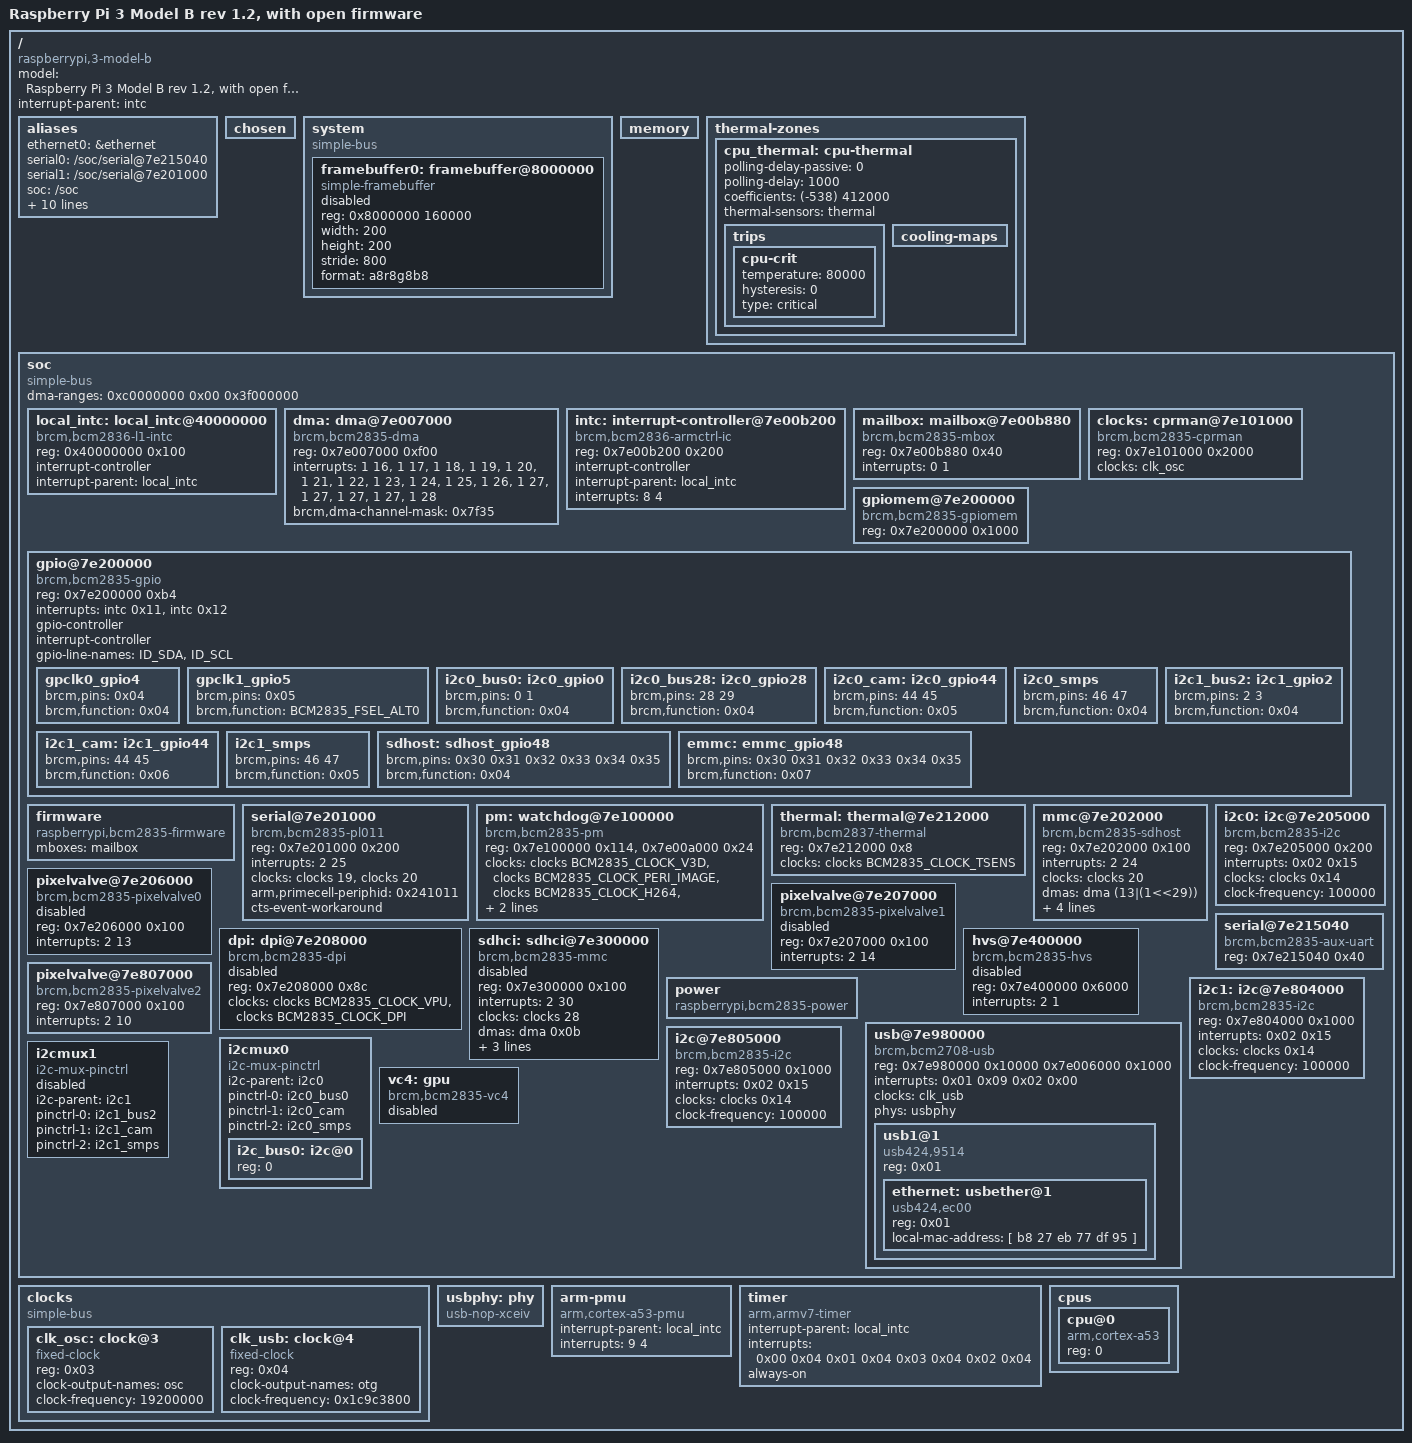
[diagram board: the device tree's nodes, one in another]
/dts-v1/;

// #define IRQ_TYPE_LEVEL_HIGH      4

#define BCM2835_FSEL_ALT0 4

#define BCM2835_CLOCK_VPU           20
#define BCM2835_CLOCK_V3D           21
#define BCM2835_CLOCK_ISP           22
#define BCM2835_CLOCK_H264          23
#define BCM2835_CLOCK_TSENS         27
#define BCM2835_CLOCK_PERI_IMAGE    29
#define BCM2835_CLOCK_DPI           44


/memreserve/ 0x00000000 0x00001000;
// /memreserve/ 0x20000000 0x1000000; // 16mb of MMIO

/ {
  compatible = "raspberrypi,3-model-b", "brcm,bcm2837";
  model = "Raspberry Pi 3 Model B rev 1.2, with open firmware";
  #address-cells = <0x01>;
  #size-cells = <0x01>;
  interrupt-parent = <&intc>;

  aliases {
    ethernet0 = &ethernet;
    serial0 = "/soc/serial@7e215040";
    serial1 = "/soc/serial@7e201000";
    soc = "/soc";
    dma = "/soc/dma@7e007000";
    intc = "/soc/interrupt-controller@7e00b200";
    uart0 = "/soc/serial@7e201000";
    sdhost = "/soc/mmc@7e202000";
    mmc0 = "/soc/mmc@7e202000";
    i2c0 = "/soc/i2c@7e205000";
    uart1 = "/soc/serial@7e215040";
    i2c1 = "/soc/i2c@7e804000";
    i2c2 = "/soc/i2c@7e805000";
    usb = "/soc/usb@7e980000";
  };
  chosen {
  };
  system {
    compatible = "simple-bus";
    #address-cells = <1>;
    #size-cells = <1>;
    ranges = <>;
    framebuffer0: framebuffer@8000000 {
      compatible = "simple-framebuffer";
      reg = <0x8000000 160000>;
      width = <200>;
      height = <200>;
      stride = <800>;
      format = "a8r8g8b8";
      status = "disabled"; // disabled by default, the bootloader will fill in the right numbers, and enable
    };
  };
  memory {
    device_type = "memory";
  };
  /*
  leds: leds {
    compatible = "gpio-leds";
    act {
      label = "ACT";
      default-state = "keep";
      linux,default-trigger = "heartbeat";
      gpios = <&gpio XX GPIO_ACTIVE_HIGH>;
    };
  };
  */
  thermal-zones {
    cpu_thermal: cpu-thermal {
      polling-delay-passive = <0>;
      polling-delay = <1000>;
      //              slope  offset
      coefficients = <(-538) 412000>;

      thermal-sensors = <&thermal>;

      trips {
        cpu-crit {
          temperature = <80000>;
          hysteresis  = <0>;
          type        = "critical";
        };
      };

      cooling-maps {
      };
    };
  };
  soc {
    compatible = "simple-bus";
    #address-cells = <1>;
    #size-cells = <1>;
    //        child       parent       length
    ranges = <0x7e000000 0x20000000 0x1000000 /* map the MMIO space to 0x3f000000 in arm, 16mb long */
              0x40000000 0x40000000 0x1000>; /* identity map the local_intc, 0x1000 bytes long */
    dma-ranges = <0xc0000000 0x00 0x3f000000>; /* map arm physical 0 to the uncached alias, 1008mb long */


    local_intc: local_intc@40000000 {
      compatible = "brcm,bcm2836-l1-intc";
      reg = <0x40000000 0x100>;
      interrupt-controller;
      #interrupt-cells = <2>;
      interrupt-parent = <&local_intc>;
    };
    dma: dma@7e007000 {
      compatible = "brcm,bcm2835-dma";
      reg = <0x7e007000 0xf00>;
      interrupts = <1 16>,
                   <1 17>,
                   <1 18>,
                   <1 19>,
                   <1 20>,
                   <1 21>,
                   <1 22>,
                   <1 23>,
                   <1 24>,
                   <1 25>,
                   <1 26>,
                   /* dma channel 11-14 share one irq */
                   <1 27>,
                   <1 27>,
                   <1 27>,
                   <1 27>,
                   /* unused shared irq for all channels */
                   <1 28>;
      interrupt-names = "dma0",
                        "dma1",
                        "dma2",
                        "dma3",
                        "dma4",
                        "dma5",
                        "dma6",
                        "dma7",
                        "dma8",
                        "dma9",
                        "dma10",
                        "dma11",
                        "dma12",
                        "dma13",
                        "dma14",
                        "dma-shared-all";
      #dma-cells = <1>;
      brcm,dma-channel-mask = <0x7f35>;
    };
    /*axiperf: axiperf {
      compatible = "brcm,bcm2835-axiperf";
      reg = <0x7e009800 0x100>,
            <0x7ee08000 0x100>;
      firmware = <&firmware>;
      //status = "disabled";
    };*/
    intc: interrupt-controller@7e00b200 {
      compatible = "brcm,bcm2836-armctrl-ic";
      reg = <0x7e00b200 0x200>;
      interrupt-controller;
      #interrupt-cells = <0x02>;
      interrupt-parent = <&local_intc>;
      interrupts = <8 4>;
    };
    mailbox: mailbox@7e00b880 {
      compatible = "brcm,bcm2835-mbox";
      reg = <0x7e00b880 0x40>;
      interrupts = <0 1>;
      #mbox-cells = <0>;
    };
    clocks: cprman@7e101000 {
      compatible = "brcm,bcm2835-cprman";
      #clock-cells = <1>;
      reg = <0x7e101000 0x2000>;

      /* CPRMAN derives almost everything from the
       * platform's oscillator.  However, the DSI
       * pixel clocks come from the DSI analog PHY.
       */
      clocks = <&clk_osc>;
              //<&dsi0 0>, <&dsi0 1>, <&dsi0 2>,
              //<&dsi1 0>, <&dsi1 1>, <&dsi1 2>;
    };
    // enable using BCM2835_DEVGPIOMEM
    gpiomem@7e200000 {
      compatible = "brcm,bcm2835-gpiomem";
      reg = <0x7e200000 0x1000>;
    };
    gpio@7e200000 {
      compatible = "brcm,bcm2835-gpio";
      reg = <0x7e200000 0xb4>;
      interrupts = <&intc 0x11>,
                   <&intc 0x12>;
      gpio-controller;
      #gpio-cells = <0x02>;
      interrupt-controller;
      #interrupt-cells = <0x02>;
      gpio-line-names = "ID_SDA", // based on arch/arm/boot/dts/bcm2835-rpi-b-plus.dts
                        "ID_SCL";
      pinctrl-names = "default";
      gpclk0_gpio4 {
        brcm,pins = <0x04>;
        brcm,function = <0x04>;
      };
      gpclk1_gpio5 {
        brcm,pins = <0x05>;
        brcm,function = <BCM2835_FSEL_ALT0>;
      };

      i2c0_bus0: i2c0_gpio0 {
        brcm,pins = <0 1>;
        brcm,function = <0x04>;
      };
      i2c0_bus28: i2c0_gpio28 {
        // do not use
        // changing altmode of 29 breaks usb
        brcm,pins = <28 29>;
        brcm,function = <0x04>;
      };
      i2c0_cam: i2c0_gpio44 {
        brcm,pins = <44 45>;
        brcm,function = <0x05>;
      };
      i2c0_smps: i2c0_smps {
        brcm,pins = <46 47>;
        brcm,function = <0x04>;
      };

      i2c1_bus2: i2c1_gpio2 {
        brcm,pins = <2 3>;
        brcm,function = <0x04>;
      };
      i2c1_cam: i2c1_gpio44 {
        brcm,pins = <44 45>;
        brcm,function = <0x06>;
      };
      i2c1_smps: i2c1_smps {
        brcm,pins = <46 47>;
        brcm,function = <0x05>;
      };

      sdhost: sdhost_gpio48 {
        brcm,pins = <0x30 0x31 0x32 0x33 0x34 0x35>;
        brcm,function = <0x04>;
      };
      emmc: emmc_gpio48 {
        brcm,pins = <0x30 0x31 0x32 0x33 0x34 0x35>;
        brcm,function = <0x07>;
      };
    };
    firmware: firmware {
      compatible = "raspberrypi,bcm2835-firmware", "simple-bus";
      mboxes = <&mailbox>;
    };
    serial@7e201000 {
      compatible = "brcm,bcm2835-pl011", "arm,pl011", "arm,primecell";
      reg = <0x7e201000 0x200>;
      interrupts = <2 25>;
      clocks = <&clocks 19>, // BCM2835_CLOCK_UART
               <&clocks 20>; // BCM2835_CLOCK_VPU
      clock-names = "uartclk", "apb_pclk";
      arm,primecell-periphid = <0x241011>;
      cts-event-workaround;
      //pinctrl-names = "default";
      //pinctrl-0 = <0x08 0x09>;
      status = "okay";
    };
    pm: watchdog@7e100000 {
      compatible = "brcm,bcm2835-pm", "brcm,bcm2835-pm-wdt";
      #power-domain-cells = <1>;
      #reset-cells = <1>;
      reg = <0x7e100000 0x114>,
            <0x7e00a000 0x24>;
      clocks = <&clocks BCM2835_CLOCK_V3D>,
               <&clocks BCM2835_CLOCK_PERI_IMAGE>,
               <&clocks BCM2835_CLOCK_H264>,
               <&clocks BCM2835_CLOCK_ISP>;
      clock-names = "v3d", "peri_image", "h264", "isp";
      system-power-controller;
    };
    thermal: thermal@7e212000 {
      compatible = "brcm,bcm2837-thermal";
      reg = <0x7e212000 0x8>;
      clocks = <&clocks BCM2835_CLOCK_TSENS>;
      #thermal-sensor-cells = <0>;
      //status = "disabled";
    };
    mmc@7e202000 {
      compatible = "brcm,bcm2835-sdhost";
      reg = <0x7e202000 0x100>;
      interrupts = <2 24>;
      clocks = <&clocks 20>; // BCM2835_CLOCK_VPU
      dmas = <&dma (13|(1<<29))>; //0x2000000d>;
      dma-names = "rx-tx";
      status = "okay";
      pinctrl-names = "default";
      pinctrl-0 = <&sdhost>;
      bus-width = <0x04>;
      brcm,overclock-50 = <0x00>;
      brcm,pio-limit = <0x01>;
      //brcm,debug = <1>;
    };
    i2c0: i2c@7e205000 {
      compatible = "brcm,bcm2835-i2c";
      reg = <0x7e205000 0x200>;
      interrupts = <0x02 0x15>;
      clocks = <&clocks 0x14>;
      #address-cells = <0x01>;
      #size-cells = <0x00>;
      //pinctrl-names = "default";
      //pinctrl-0 = <&i2c0_bus0>;
      clock-frequency = <100000>;
    };
    pixelvalve@7e206000 {
      compatible = "brcm,bcm2835-pixelvalve0";
      reg = <0x7e206000 0x100>;
      interrupts = <2 13>; /* pwa0 */
      status = "disabled";
    };

    pixelvalve@7e207000 {
      compatible = "brcm,bcm2835-pixelvalve1";
      reg = <0x7e207000 0x100>;
      interrupts = <2 14>; /* pwa1 */
      status = "disabled";
    };
    dpi: dpi@7e208000 {
      compatible = "brcm,bcm2835-dpi";
      reg = <0x7e208000 0x8c>;
      clocks = <&clocks BCM2835_CLOCK_VPU>,
               <&clocks BCM2835_CLOCK_DPI>;
      clock-names = "core", "pixel";
      #address-cells = <1>;
      #size-cells = <0>;
      status = "disabled";
    };
    serial@7e215040 {
      compatible = "brcm,bcm2835-aux-uart";
      reg = <0x7e215040 0x40>;
      //interrupts = <0x01 0x1d>;
      //clocks = <0x12 0x00>;
      status = "okay";
      //pinctrl-names = "default";
      //pinctrl-0 = <0x13>;
      //phandle = <0x23>;
    };
    sdhci: sdhci@7e300000 {
      compatible = "brcm,bcm2835-mmc", "brcm,bcm2835-sdhci";
      reg = <0x7e300000 0x100>;
      interrupts = <2 30>;
      clocks = <&clocks 28>; // BCM2835_CLOCK_EMMC
      dmas = <&dma 0x0b>;
      dma-names = "rx-tx";
      brcm,overclock-50 = <0x00>;
      status = "disabled";
      pinctrl-names = "default";
      pinctrl-0 = <&emmc>;
      bus-width = <0x04>;
    };
    hvs@7e400000 {
      // not currently functional
      status = "disabled";
      compatible = "brcm,bcm2835-hvs";
      reg = <0x7e400000 0x6000>;
      interrupts = <2 1>;
    };
    /*
    vchiq: mailbox@7e00b840 {
      compatible = "brcm,bcm2835-vchiq";
      reg = <0x7e00b840 0x3c>;
      interrupts = <0 2>;
    };*/
    pixelvalve@7e807000 {
      compatible = "brcm,bcm2835-pixelvalve2";
      reg = <0x7e807000 0x100>;
      interrupts = <2 10>; /* pixelvalve */
    };
    power {
      compatible = "raspberrypi,bcm2835-power";
      //firmware = <0x07>;
      #power-domain-cells = <0x01>;
    };
    usb@7e980000 {
      compatible = "brcm,bcm2708-usb";
      reg = <0x7e980000 0x10000 0x7e006000 0x1000>;
      interrupts = <0x01 0x09 0x02 0x00>;
      #address-cells = <0x01>;
      #size-cells = <0x00>;
      clocks = <&clk_usb>;
      clock-names = "otg";
      phys = <&usbphy>;
      phy-names = "usb2-phy";
      interrupt-names = "usb", "soft";
      //power-domains = <&power 0x06>;

      usb1@1 {
        compatible = "usb424,9514";
        reg = <0x01>;
        #address-cells = <0x01>;
        #size-cells = <0x00>;

        ethernet: usbether@1 {
          compatible = "usb424,ec00";
          reg = <0x01>;
          local-mac-address = [ b8 27 eb 77 df 95 ];
        };
      };
    };
    i2c1: i2c@7e804000 {
      compatible = "brcm,bcm2835-i2c";
      reg = <0x7e804000 0x1000>;
      interrupts = <0x02 0x15>;
      clocks = <&clocks 0x14>;
      #address-cells = <0x01>;
      #size-cells = <0x00>;
      //pinctrl-names = "default";
      //pinctrl-0 = <&i2c1>;
      clock-frequency = <100000>; // 100khz
    };
    i2c@7e805000 { // i2c2
      compatible = "brcm,bcm2835-i2c";
      reg = <0x7e805000 0x1000>;
      interrupts = <0x02 0x15>;
      clocks = <&clocks 0x14>;
      #address-cells = <0x01>;
      #size-cells = <0x00>;
      clock-frequency = <100000>; // 100khz
    };
    i2cmux0 {
      compatible = "i2c-mux-pinctrl";
      #address-cells = <1>;
      #size-cells = <0>;
      i2c-parent = <&i2c0>;
      pinctrl-names = "bus0", "cam0", "smps0";
      pinctrl-0 = <&i2c0_bus0>;
      pinctrl-1 = <&i2c0_cam>;
      pinctrl-2 = <&i2c0_smps>;

      i2c_bus0: i2c@0 {
        reg = <0>;
        #address-cells = <1>;
        #size-cells = <0>;
      };
    };

    i2cmux1 {
      compatible = "i2c-mux-pinctrl";
      #address-cells = <1>;
      #size-cells = <0>;
      i2c-parent = <&i2c1>;
      pinctrl-names = "bus2", "cam1", "smps1";
      pinctrl-0 = <&i2c1_bus2>;
      pinctrl-1 = <&i2c1_cam>;
      pinctrl-2 = <&i2c1_smps>;
      status = "disabled"; // not much need for the 2nd mux
    };
    vc4: gpu {
      compatible = "brcm,bcm2835-vc4";
      status = "disabled";
    };
  };
  clocks {
    compatible = "simple-bus";
    #address-cells = <0x01>;
    #size-cells = <0x00>;

    clk_osc: clock@3 {
      compatible = "fixed-clock";
      reg = <0x03>;
      #clock-cells = <0x00>;
      clock-output-names = "osc";
      clock-frequency = <19200000>; // 19.2mhz
    };

    clk_usb: clock@4 {
      compatible = "fixed-clock";
      reg = <0x04>;
      #clock-cells = <0x00>;
      clock-output-names = "otg";
      clock-frequency = <0x1c9c3800>; // 480mhz
    };
  };
  usbphy: phy {
    compatible = "usb-nop-xceiv";
    #phy-cells = <0x00>;
  };
  arm-pmu {
    compatible = "arm,cortex-a53-pmu";
    interrupt-parent = <&local_intc>;
    interrupts = <9 4>;
  };
  timer {
    compatible = "arm,armv7-timer";
    interrupt-parent = <&local_intc>;
    interrupts = <0x00 0x04
                  0x01 0x04
                  0x03 0x04
                  0x02 0x04>;
    always-on;
  };
  cpus {
    #address-cells = <1>;
    #size-cells = <0>;
    cpu@0 {
      device_type = "cpu";
      compatible = "arm,cortex-a53";
      reg = <0>;
    };
  };
};
